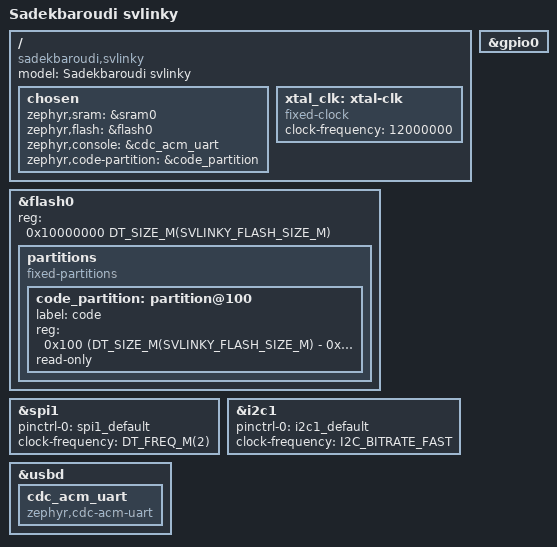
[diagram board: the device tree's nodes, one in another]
/*
 * Copyright (c) 2021 Yonatan Schachter
 *
 * SPDX-License-Identifier: Apache-2.0
 */

/dts-v1/;

#include <rpi_pico/rp2040.dtsi>
#include "sadekbaroudi_svlinky-pinctl.dtsi"
#include "sparkfun_pro_micro.dtsi"
#include "vik_connector.dtsi"
#include <freq.h>

/ {
	model = "Sadekbaroudi svlinky";
	compatible = "sadekbaroudi,svlinky", "raspberrypi,rp2040";

	chosen {
		zephyr,sram = &sram0;
		zephyr,flash = &flash0;
		zephyr,console = &cdc_acm_uart;
		zephyr,code-partition = &code_partition;
	};

	xtal_clk: xtal-clk {
		compatible = "fixed-clock";
		clock-frequency = <12000000>;
		#clock-cells = <0>;
	};
};

#define SVLINKY_FLASH_SIZE_M 4

&flash0 {
	/* 8MB of flash minus the 0x100 used for
	 * the second stage bootloader
	 */
	reg = <0x10000000 DT_SIZE_M(SVLINKY_FLASH_SIZE_M)>;

	partitions {
		compatible = "fixed-partitions";
		#address-cells = <1>;
		#size-cells = <1>;

		/*
		 * Start at the beginning of usable flash, SVLINKY_FLASH_SIZE_M MB minus the
		 * second stage space and the 16 KiB reserved for settings
		 */
		code_partition: partition@100 {
			label = "code";
			reg = <0x100 (DT_SIZE_M(SVLINKY_FLASH_SIZE_M) - 0x100)>;
			read-only;
		};
	};
};

&spi1 {
	pinctrl-0 = <&spi1_default>;
	pinctrl-names = "default";
	clock-frequency = <DT_FREQ_M(2)>;
};

/*
&i2c0 {
	pinctrl-0 = <&i2c0_default>;
	pinctrl-names = "default";
	clock-frequency = <I2C_BITRATE_FAST>;
};
*/

&i2c1 {
	pinctrl-0 = <&i2c1_default>;
	pinctrl-names = "default";
	clock-frequency = <I2C_BITRATE_FAST>;
};

&gpio0 {
	status = "okay";
};

zephyr_udc0: &usbd {
	status = "okay";
	cdc_acm_uart: cdc_acm_uart {
		compatible = "zephyr,cdc-acm-uart";
	};
};
